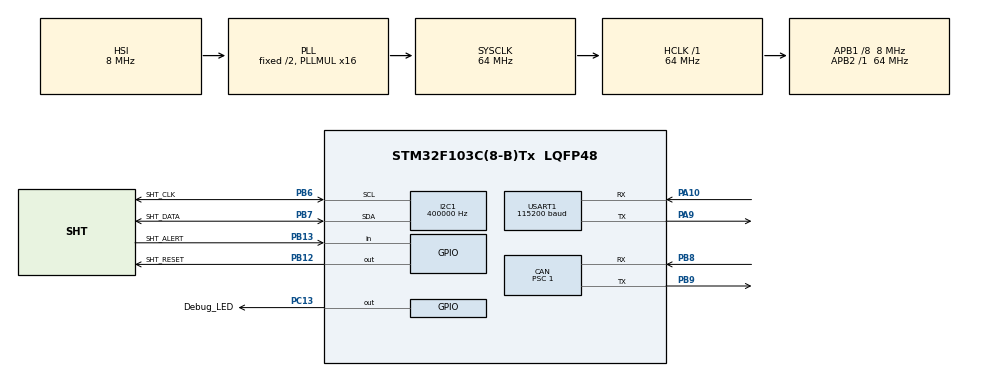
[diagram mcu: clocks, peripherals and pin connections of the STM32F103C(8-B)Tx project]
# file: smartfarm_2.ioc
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Mcu.Family=STM32F1
NVIC.I2C1_EV_IRQn=true\:0\:0\:false\:false\:true\:true\:true
PA10.Mode=Asynchronous
I2C1.GeneralCallMode=I2C_GENERALCALL_DISABLE
CAN.ABOM=DISABLE
USART1.BaudRate=115200
CAN.RFLM=DISABLE
USART1.WordLength=WORDLENGTH_8B
PC13-TAMPER-RTC.Signal=GPIO_Output
PB6.GPIO_Label=SHT_CLK
CAN.SJW=CAN_SJW_1TQ
RCC.APB1CLKDivider=RCC_HCLK_DIV8
PB13.GPIO_Label=SHT_ALERT
PB13.Signal=GPIO_Input
VP_SYS_VS_ND.Mode=No_Debug
CAN.CalculateTimeBit=2000
RCC.SYSCLKSource=RCC_SYSCLKSOURCE_PLLCLK
ProjectManager.StackSize=0x600
I2C1.DualAddressMode=I2C_DUALADDRESS_DISABLE
CAN.TTCM=DISABLE
PA9.Mode=Asynchronous
CAN.BS2=CAN_BS2_2TQ
CAN.Prescaler=1
CAN.BS1=CAN_BS1_13TQ
USART1.StopBits=STOPBITS_1
I2C1.ClockSpeed=400000
ProjectManager.TargetToolchain=TrueSTUDIO
I2C1.I2C_Mode=I2C_Fast
RCC.HCLKFreq_Value=64000000
RCC.FLatency=FLASH_LATENCY_2
PB9.Mode=Master
I2C1.DutyCycle=I2C_DUTYCYCLE_2
RCC.APB2TimFreq_Value=64000000
PA9.Signal=USART1_TX
USART1.Parity=PARITY_NONE
PB6.Signal=I2C1_SCL
PB12.PinState=GPIO_PIN_SET
PB6.Mode=I2C
I2C1.AddressingMode=I2C_ADDRESSINGMODE_7BIT
RCC.USBFreq_Value=64000000
CAN.Mode=CAN_MODE_NORMAL
RCC.AHBFreq_Value=64000000
board=custom
PC13-TAMPER-RTC.GPIO_Label=Debug_LED
RCC.PLLMUL=RCC_PLL_MUL16
PB12.GPIO_Label=SHT_RESET
RCC.APB2Freq_Value=64000000
I2C1.NoStretchMode=I2C_NOSTRETCH_DISABLE
USART1.Mode=MODE_TX_RX
NVIC.USB_LP_CAN1_RX0_IRQn=true\:0\:0\:false\:false\:true\:true\:true
CAN.NART=ENABLE
PB7.Signal=I2C1_SDA
NVIC.I2C1_ER_IRQn=true\:0\:0\:false\:false\:true\:true\:true
Mcu.Name=STM32F103C(8-B)Tx
CAN.CalculateTimeQuantum=125.0
I2C1.OwnAddress=0x44
PB7.GPIO_Label=SHT_DATA
RCC.SYSCLKFreq_VALUE=64000000
Mcu.Package=LQFP48
PB9.Signal=CAN_TX
USART1.VirtualMode=VM_ASYNC
PB7.Mode=I2C
PA10.Signal=USART1_RX
ProjectManager.HeapSize=0x400
NVIC.PriorityGroup=NVIC_PRIORITYGROUP_4
PB8.Mode=Master
CAN.TXFP=DISABLE
RCC.APB1TimFreq_Value=16000000
PB8.Signal=CAN_RX
CAN.AWUM=DISABLE
NVIC.USART1_IRQn=true\:0\:0\:false\:true\:true\:1\:true\:true
RCC.APB1Freq_Value=8000000
PB12.Signal=GPIO_Output

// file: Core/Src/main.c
/* USER CODE BEGIN Header */
/**
  ******************************************************************************
  * @file           : main.c
  * @brief          : Main program body
  ******************************************************************************
  * @attention
  *
  * <h2><center>&copy; Copyright (c) 2021 STMicroelectronics.
  * All rights reserved.</center></h2>
  *
  * This software component is licensed by ST under BSD 3-Clause license,
  * the "License"; You may not use this file except in compliance with the
  * License. You may obtain a copy of the License at:
  *                        opensource.org/licenses/BSD-3-Clause
  *
  ******************************************************************************
  */
/* USER CODE END Header */
#include "main.h"
#include "can.h"
#include "i2c.h"
#include "usart.h"
#include "gpio.h"

/* USER CODE BEGIN Includes */
#include "mainapp.h"
/* USER CODE END Includes */

void SystemClock_Config(void);
static void MX_NVIC_Init(void);
/* USER CODE BEGIN PFP */
int _write(int file, char* p, int len)
{
	HAL_UART_Transmit(&huart1, (uint8_t*)p, len, 10);
	return len;
}
/* USER CODE END PFP */

int main(void)
{

  /* MCU Configuration--------------------------------------------------------*/

  /* Reset of all peripherals, Initializes the Flash interface and the Systick. */
  HAL_Init();

  /* Configure the system clock */
  SystemClock_Config();

  /* Initialize all configured peripherals */
  MX_GPIO_Init();
  MX_USART1_UART_Init();
  MX_CAN_Init();
  MX_I2C1_Init();

  /* Initialize interrupts */
  MX_NVIC_Init();
  /* USER CODE BEGIN 2 */
  setup();

  /* USER CODE END 2 */

  /* Infinite loop */
  /* USER CODE BEGIN WHILE */
  while (1)
  {
	  loop();
    /* USER CODE END WHILE */

  }
}

void SystemClock_Config(void)
{
  RCC_OscInitTypeDef RCC_OscInitStruct = {0};
  RCC_ClkInitTypeDef RCC_ClkInitStruct = {0};

  /** Initializes the RCC Oscillators according to the specified parameters
  * in the RCC_OscInitTypeDef structure.
  */
  RCC_OscInitStruct.OscillatorType = RCC_OSCILLATORTYPE_HSI;
  RCC_OscInitStruct.HSIState = RCC_HSI_ON;
  RCC_OscInitStruct.HSICalibrationValue = RCC_HSICALIBRATION_DEFAULT;
  RCC_OscInitStruct.PLL.PLLState = RCC_PLL_ON;
  RCC_OscInitStruct.PLL.PLLSource = RCC_PLLSOURCE_HSI_DIV2;
  RCC_OscInitStruct.PLL.PLLMUL = RCC_PLL_MUL16;
  if (HAL_RCC_OscConfig(&RCC_OscInitStruct) != HAL_OK)
  {
    Error_Handler();
  }
  /** Initializes the CPU, AHB and APB buses clocks
  */
  RCC_ClkInitStruct.ClockType = RCC_CLOCKTYPE_HCLK|RCC_CLOCKTYPE_SYSCLK
                              |RCC_CLOCKTYPE_PCLK1|RCC_CLOCKTYPE_PCLK2;
  RCC_ClkInitStruct.SYSCLKSource = RCC_SYSCLKSOURCE_PLLCLK;
  RCC_ClkInitStruct.AHBCLKDivider = RCC_SYSCLK_DIV1;
  RCC_ClkInitStruct.APB1CLKDivider = RCC_HCLK_DIV8;
  RCC_ClkInitStruct.APB2CLKDivider = RCC_HCLK_DIV1;

  if (HAL_RCC_ClockConfig(&RCC_ClkInitStruct, FLASH_LATENCY_2) != HAL_OK)
  {
    Error_Handler();
  }
}

/**
  * @brief NVIC Configuration.
  * @retval None
  */
static void MX_NVIC_Init(void)
{
  /* USART1_IRQn interrupt configuration */
  HAL_NVIC_SetPriority(USART1_IRQn, 0, 0);
  HAL_NVIC_EnableIRQ(USART1_IRQn);
}

void Error_Handler(void)
{
}

/************************ (C) COPYRIGHT STMicroelectronics *****END OF FILE****/
